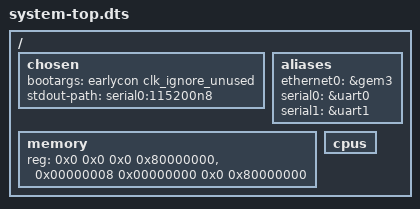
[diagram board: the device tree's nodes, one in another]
/*
 * CAUTION: This file is automatically generated by Xilinx.
 * Version:  
 * Today is: Thu Jul 26 12:03:48 2018
*/


/dts-v1/;
/include/ "zynqmp.dtsi"
/include/ "zynqmp-clk-ccf.dtsi"
/include/ "zcu102-revb.dtsi"
/include/ "pl.dtsi"
/include/ "pcw.dtsi"
/ {
	chosen {
		bootargs = "earlycon clk_ignore_unused";
		stdout-path = "serial0:115200n8";
	};
	aliases {
		ethernet0 = &gem3;
		serial0 = &uart0;
		serial1 = &uart1;
	};
	memory {
		device_type = "memory";
		reg = <0x0 0x0 0x0 0x80000000>, <0x00000008 0x00000000 0x0 0x80000000>;
	};
	cpus {
	};
};
#include "system-user.dtsi"
